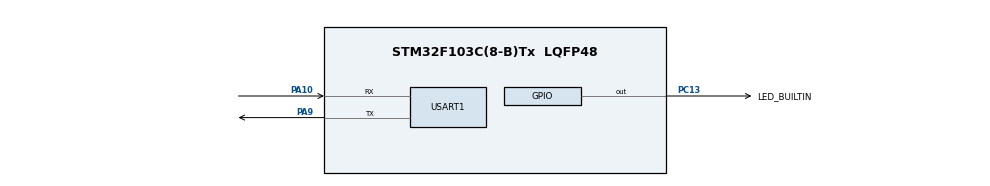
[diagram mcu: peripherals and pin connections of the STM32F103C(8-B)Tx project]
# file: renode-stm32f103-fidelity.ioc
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Mcu.Family=STM32F1
Mcu.Name=STM32F103C(8-B)Tx
Mcu.Package=LQFP48
NVIC.PriorityGroup=NVIC_PRIORITYGROUP_4
NVIC.TIM2_IRQn=true\:2\:0\:true\:false\:true\:true\:true\:true
NVIC.TIM3_IRQn=true\:12\:0\:true\:false\:true\:true\:true\:true
NVIC.USART1_IRQn=true\:8\:0\:true\:false\:true\:true\:true\:true
PA10.Mode=Asynchronous
PA10.Signal=USART1_RX
PA13.Mode=Serial_Wire
PA13.Signal=SYS_JTMS-SWDIO
PA14.Mode=Serial_Wire
PA14.Signal=SYS_JTCK-SWCLK
PA9.Mode=Asynchronous
PA9.Signal=USART1_TX
PC13-TAMPER-RTC.GPIO_Label=LED_BUILTIN
PC13-TAMPER-RTC.PinState=GPIO_PIN_SET
PC13-TAMPER-RTC.Signal=GPIO_Output
ProjectManager.HeapSize=0x200
ProjectManager.StackSize=0x400
ProjectManager.TargetToolchain=CMake
RCC.AHBFreq_Value=8000000
RCC.APB1Freq_Value=8000000
RCC.APB1TimFreq_Value=8000000
RCC.APB2Freq_Value=8000000
RCC.APB2TimFreq_Value=8000000
RCC.HCLKFreq_Value=8000000
RCC.PLLMUL=RCC_PLL_MUL3
RCC.SYSCLKFreq_VALUE=8000000
RCC.USBFreq_Value=12000000
TIM2.AutoReloadPreload=TIM_AUTORELOAD_PRELOAD_ENABLE
TIM2.Period=999
TIM2.Prescaler=7
TIM3.AutoReloadPreload=TIM_AUTORELOAD_PRELOAD_ENABLE
TIM3.Period=999
TIM3.Prescaler=7
USART1.VirtualMode=VM_ASYNC
VP_TIM2_VS_ClockSourceINT.Mode=Internal
VP_TIM3_VS_ClockSourceINT.Mode=Internal
board=custom

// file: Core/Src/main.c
/* USER CODE BEGIN Header */
/**
  ******************************************************************************
  * @file           : main.c
  * @brief          : Main program body
  ******************************************************************************
  * @attention
  *
  * Copyright (c) 2026 STMicroelectronics.
  * All rights reserved.
  *
  * This software is licensed under terms that can be found in the LICENSE file
  * in the root directory of this software component.
  * If no LICENSE file comes with this software, it is provided AS-IS.
  *
  ******************************************************************************
  */
/* USER CODE END Header */
#include "main.h"
#include "tim.h"
#include "usart.h"
#include "gpio.h"

void SystemClock_Config(void);

int main(void)
{

  /* MCU Configuration--------------------------------------------------------*/

  /* Reset of all peripherals, Initializes the Flash interface and the Systick. */
  LL_APB2_GRP1_EnableClock(LL_APB2_GRP1_PERIPH_AFIO);
  LL_APB1_GRP1_EnableClock(LL_APB1_GRP1_PERIPH_PWR);

  /* System interrupt init*/
  NVIC_SetPriorityGrouping(NVIC_PRIORITYGROUP_4);

  /* SysTick_IRQn interrupt configuration */
  NVIC_SetPriority(SysTick_IRQn, NVIC_EncodePriority(NVIC_GetPriorityGrouping(),15, 0));

  /** NOJTAG: JTAG-DP Disabled and SW-DP Enabled
  */
  LL_GPIO_AF_Remap_SWJ_NOJTAG();

  /* Configure the system clock */
  SystemClock_Config();

  /* Initialize all configured peripherals */
  MX_GPIO_Init();
  MX_TIM2_Init();
  MX_USART1_UART_Init();
  MX_TIM3_Init();
  /* USER CODE BEGIN 2 */

  /* ── Dispatch de cenário ──────────────────────────────────────────────
   * O build define -DSCENARIO_<X> (SANDBOX | A | B | C1..C4) via flag
   * -DSCENARIO=*. Este bloco é o ÚNICO ponto modificado neste arquivo.
   * Ele sobrevive a "Generate Code" do CubeMX porque está entre
   * USER CODE BEGIN/END.
   *
   * Cada cenário vive em src/<cenario>.c e exporta uma função
   * <cenario>_main(). Esta função não retorna — o cenário controla o
   * loop principal e entra em __WFI() entre eventos.
   *
   * ISOLAMENTO: os MX_*_Init() acima são incondicionais (região gerada,
   * não editável). Cada cX_main() começa quarentenando os periféricos
   * que não usa (NVIC_DisableIRQ + clock gate) — ver cada src/c*.c.
   * ──────────────────────────────────────────────────────────────────── */

  extern void sandbox_main(void);
  extern void scenario_a_main(void);
  extern void scenario_b_main(void);
  extern void c1_core_main(void);
  extern void c2_irq_baseline_main(void);
  extern void c3_irq_arbitration_main(void);
  extern void c4_usart_main(void);
  extern void echo_peer_main(void);

#if defined(SCENARIO_SANDBOX)
  sandbox_main();
#elif defined(SCENARIO_A)
  scenario_a_main();
#elif defined(SCENARIO_B)
  scenario_b_main();
#elif defined(SCENARIO_C1)
  c1_core_main();
#elif defined(SCENARIO_C2)
  c2_irq_baseline_main();
#elif defined(SCENARIO_C3)
  c3_irq_arbitration_main();
#elif defined(SCENARIO_C4)
  c4_usart_main();
#elif defined(SCENARIO_ECHO)
  echo_peer_main();
#else
  #error "No SCENARIO_* defined. Build com -DSCENARIO=SANDBOX|A|B|C1|C2|C3|C4"
#endif

  /* sandbox.c e scenario_a.c entram em loop infinito via __WFI();
   * scenario_b.c idem. O while(1) abaixo NUNCA é alcançado em prática,
   * mas o compilador exige algum statement após a chamada. */
  /* USER CODE END 2 */

  /* Infinite loop */
  while (1)
  {

  }
}

void SystemClock_Config(void)
{
  LL_FLASH_SetLatency(LL_FLASH_LATENCY_0);
  while(LL_FLASH_GetLatency()!= LL_FLASH_LATENCY_0)
  {
  }
  LL_RCC_HSI_SetCalibTrimming(16);
  LL_RCC_HSI_Enable();

   /* Wait till HSI is ready */
  while(LL_RCC_HSI_IsReady() != 1)
  {

  }
  LL_RCC_SetAHBPrescaler(LL_RCC_SYSCLK_DIV_1);
  LL_RCC_SetAPB1Prescaler(LL_RCC_APB1_DIV_1);
  LL_RCC_SetAPB2Prescaler(LL_RCC_APB2_DIV_1);
  LL_RCC_SetSysClkSource(LL_RCC_SYS_CLKSOURCE_HSI);

   /* Wait till System clock is ready */
  while(LL_RCC_GetSysClkSource() != LL_RCC_SYS_CLKSOURCE_STATUS_HSI)
  {

  }
  LL_Init1msTick(8000000);
  LL_SetSystemCoreClock(8000000);
}

void Error_Handler(void)
{
  __disable_irq();
  while (1)
  {
  }
}
